# R7FA4L1BD register map
Vendor: Renesas Electronics Corporation; Series: RA4; File version: 0.90.02
CPU: CM33 r0p4, little endian, MPU, FPU, VTOR, 4 interrupt priority bits, 96 interrupts
Registers are 32-bit, read-write, reset 0x0 unless marked. A register's access mark holds for its fields unless they carry their own. Offsets are from the block's base; [hi:lo] are bit positions; {n}, {i} and the like mark numbered series.

## SYSC — System Control
Base 0x4001E000
0x0C SBYCR 16-bit — Standby Control Register
  [15] SSBY — Software Standby Mode Select
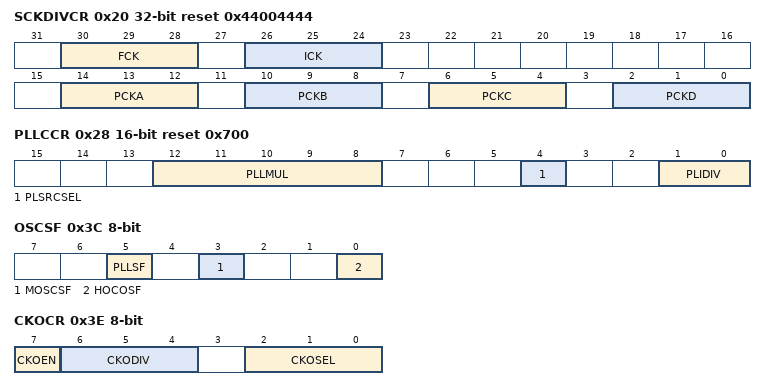
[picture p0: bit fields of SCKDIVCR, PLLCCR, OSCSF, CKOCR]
0x20 SCKDIVCR reset 0x44004444 — System Clock Division Control Register
  [30:28] FCK — FlashIF Clock (FCLK) Select
  [26:24] ICK — System Clock (ICLK) Select
  [14:12] PCKA — Peripheral Module Clock A (PCLKA) Select
  [10:8] PCKB — Peripheral Module Clock B (PCLKB) Select
  [6:4] PCKC — Peripheral Module Clock C (PCLKC) Select
  [2:0] PCKD — Peripheral Module Clock D (PCLKD) Select
0x26 SCKSCR 8-bit reset 0x1 — System Clock Source Control Register
  [2:0] CKSEL — Clock Source Select
0x28 PLLCCR 16-bit reset 0x700 — PLL Clock Control Register
  [12:8] PLLMUL range 0x13..0x3B — PLL Frequency Multiplication Factor Select
  [4] PLSRCSEL — PLL Clock Source Select
  [1:0] PLIDIV — PLL Input Frequency Division Ratio Select
0x2A PLLCR 8-bit reset 0x1 — PLL Control Register
  [0] PLLSTP — PLL Stop Control
0x31 MEMWAIT 8-bit — Memory Wait Cycle Control Register for Code Flash
  [1:0] MEMWAIT — Memory Wait Cycle Select for Code Flash
0x32 MOSCCR 8-bit reset 0x1 — Main Clock Oscillator Control Register
  [0] MOSTP — Main Clock Oscillator Stop
0x36 HOCOCR 8-bit (reset mask 0xFE) — High,Speed On,Chip Oscillator Control Register
  [0] HCSTP — HOCO Stop
0x38 MOCOCR 8-bit — Middle,Speed On,Chip Oscillator Control Register
  [0] MCSTP — MOCO Stop
0x3C OSCSF 8-bit ro (reset mask 0xFE) — Oscillation Stabilization Flag Register
  [5] PLLSF — PLL Clock Oscillation Stabilization Flag
  [3] MOSCSF — Main Clock Oscillation Stabilization Flag
  [0] HOCOSF — HOCO Clock Oscillation Stabilization Flag
0x3E CKOCR 8-bit — Clock Out Control Register
  [7] CKOEN — Clock Out Enable
  [6:4] CKODIV — Clock Output Frequency Division Ratio
  [2:0] CKOSEL — Clock Out Source Select
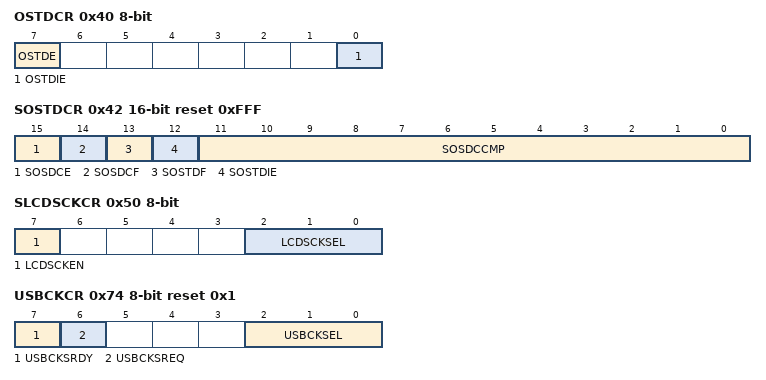
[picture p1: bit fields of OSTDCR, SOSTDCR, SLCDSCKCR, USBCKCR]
0x40 OSTDCR 8-bit — Oscillation Stop Detection Control Register
  [7] OSTDE — Oscillation Stop Detection Function Enable
  [0] OSTDIE — Oscillation Stop Detection Interrupt Enable
0x41 OSTDSR 8-bit — Oscillation Stop Detection Status Register
  [0] OSTDF — Oscillation Stop Detection Flag
0x42 SOSTDCR 16-bit reset 0xFFF — Sub,Clock Oscillation Stop Detection Control Register
  [15] SOSDCE — Control of Sub,Clock Oscillation Stop Detector Operation
  [14] SOSDCF ro — Status of Sub,Clock Oscillation Stop Detector Operation
  [13] SOSTDF ro — Sub,Clock Oscillation Stop Detection Flag
  [12] SOSTDIE — Sub,Clock Oscillation Stop Detection Interrupt Enable
  [11:0] SOSDCCMP — Sub,Clock Oscillation Stop Detection Time
0x50 SLCDSCKCR 8-bit — Segment LCD Source Clock Control Register
  [7] LCDSCKEN — Segment LCD Source Clock (LCDSRCCLK) Out Enable
  [2:0] LCDSCKSEL — Segment LCD Source Clock (LCDSRCCLK) Select
0x61 MOCOUTCR 8-bit — MOCO User Trimming Control Register
  [7:0] MOCOUTRM — MOCO User Trimming
0x62 HOCOUTCR 8-bit — HOCO User Trimming Control Register
  [7:0] HOCOUTRM — HOCO User Trimming
0x6E CANFDCKDIVCR 8-bit — CANFD Clock Division Control Register
  [2:0] CANFDCKDIV — CANFD clock (CANFDCLK) Division Select
0x71 I3CCKDIVCR 8-bit — I3C Clock Division Control Register
  [2:0] I3CCKDIV — I3C Clock (I3CCLK) Division Select
0x74 USBCKCR 8-bit reset 0x1 — USB Clock Control Register
  [7] USBCKSRDY ro — USB Clock (USBCLK) Switching Ready state flag
  [6] USBCKSREQ — USB Clock (USBCLK) Switching Request
  [2:0] USBCKSEL — USB Clock (USBCLK) Source Select
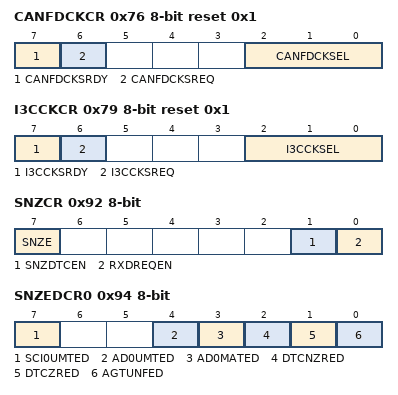
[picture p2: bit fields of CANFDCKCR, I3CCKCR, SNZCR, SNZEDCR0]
0x76 CANFDCKCR 8-bit reset 0x1 — CANFD Clock Control Register
  [7] CANFDCKSRDY ro — CANFD clock (CANFDCLK) Switching Ready State Flag
  [6] CANFDCKSREQ — CANFD clock (CANFDCLK) Switching Request
  [2:0] CANFDCKSEL — CANFD clock (CANFDCLK) Source Select
0x79 I3CCKCR 8-bit reset 0x1 — I3C Clock Control Register
  [7] I3CCKSRDY ro — I3C clock (I3CCLK) Switching Ready State Flag
  [6] I3CCKSREQ — I3C clock (I3CCLK) Switching Request
  [2:0] I3CCKSEL — I3C clock (I3CCLK) Source Select
0x92 SNZCR 8-bit — Snooze Control Register
  [7] SNZE — Snooze mode Enable
  [1] SNZDTCEN — DTC Enable in Snooze mode
  [0] RXDREQEN — RXD0 Snooze Request Enable
0x94 SNZEDCR0 8-bit — Snooze End Control Register 0
  [7] SCI0UMTED — SCI0 Address Mismatch Snooze End Enable
  [4] AD0UMTED — ADC12 Compare Mismatch Snooze End Enable
  [3] AD0MATED — ADC12 Compare Match Snooze End Enable
  [2] DTCNZRED — Not Last DTC Transmission Completion Snooze End Enable
  [1] DTCZRED — Last DTC Transmission Completion Snooze End Enable
  [0] AGTUNFED — AGT1 Underflow Snooze End Enable
0x95 SNZEDCR1 8-bit — Snooze End Control Register 1
  [1] CTSUNAJED — CTSU non,touch automatic judgment Snooze End Enable
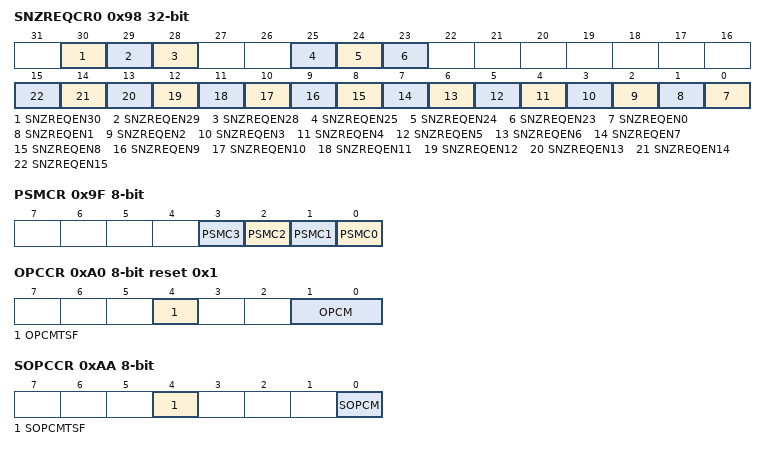
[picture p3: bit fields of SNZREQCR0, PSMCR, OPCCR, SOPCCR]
0x98 SNZREQCR0 — Snooze Request Control Register 0
  [30] SNZREQEN30 — Enable AGT1 compare match B snooze request
  [29] SNZREQEN29 — Enable AGT1 compare match A snooze request
  [28] SNZREQEN28 — Enable AGT1 underflow snooze request
  [25] SNZREQEN25 — Enable RTC period snooze request
  [24] SNZREQEN24 — Enable RTC alarm snooze request
  [23] SNZREQEN23 — Enable ACMP_LP0 snooze request
  [n] SNZREQEN{n} (n=0..15) — Enable IRQ{n} pin snooze request
0x9F PSMCR 8-bit — Power Save Memory Control Register
  [n] PSMC{n} (n=0..3) — Power Save Memory Control bit {n}
0xA0 OPCCR 8-bit reset 0x1 — Operating Power Control Register
  [4] OPCMTSF ro — Operating Power Control Mode Transition Status Flag
  [1:0] OPCM — Operating Power Control Mode Select
0xA2 MOSCWTCR 8-bit reset 0x5 — Main Clock Oscillator Wait Control Register
  [3:0] MSTS — Main Clock Oscillator Wait Time Setting
0xAA SOPCCR 8-bit — Sub Operating Power Control Register
  [4] SOPCMTSF ro — Operating Power Control Mode Transition Status Flag
  [0] SOPCM — Sub Operating Power Control Mode Select
0xAC LDOCR 8-bit — LDO Control Register
  [0] CHG0 — Charge up 0
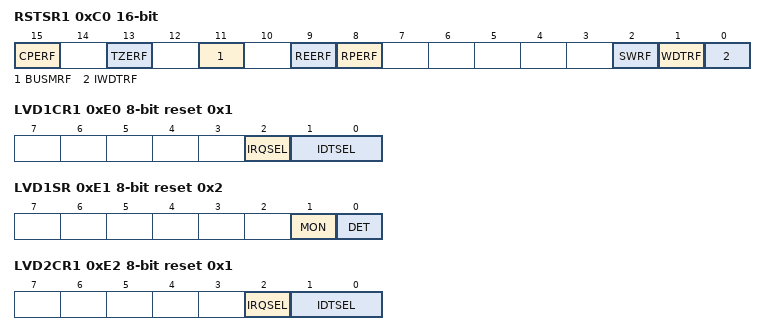
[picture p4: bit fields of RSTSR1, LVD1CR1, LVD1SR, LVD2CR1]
0xC0 RSTSR1 16-bit (reset mask 0x54F8) — Reset Status Register 1
  [15] CPERF — Cache Parity Error Reset Detect Flag
  [13] TZERF — TrustZone Error Reset Detect Flag
  [11] BUSMRF — Bus Master MPU Error Reset Detect Flag
  [9] REERF — SRAM ECC Error Reset Detect Flag
  [8] RPERF — SRAM Parity Error Reset Detect Flag
  [2] SWRF — Software Reset Detect Flag
  [1] WDTRF — Watchdog Timer Reset Detect Flag
  [0] IWDTRF — Independent Watchdog Timer Reset Detect Flag
0xE0 LVD1CR1 8-bit reset 0x1 — Voltage Monitor 1 Circuit Control Register
  [2] IRQSEL — Voltage Monitor 1 Interrupt Type Select
  [1:0] IDTSEL — Voltage Monitor 1 Interrupt Generation Condition Select
0xE1 LVD1SR 8-bit reset 0x2 — Voltage Monitor 1 Circuit Status Register
  [1] MON ro — Voltage Monitor 1 Signal Monitor Flag
  [0] DET — Voltage Monitor 1 Voltage Variation Detection Flag
0xE2 LVD2CR1 8-bit reset 0x1 — Voltage Monitor 2 Circuit Control Register 1
  [2] IRQSEL — Voltage Monitor 2 Interrupt Type Select
  [1:0] IDTSEL — Voltage Monitor 2 Interrupt Generation Condition Select
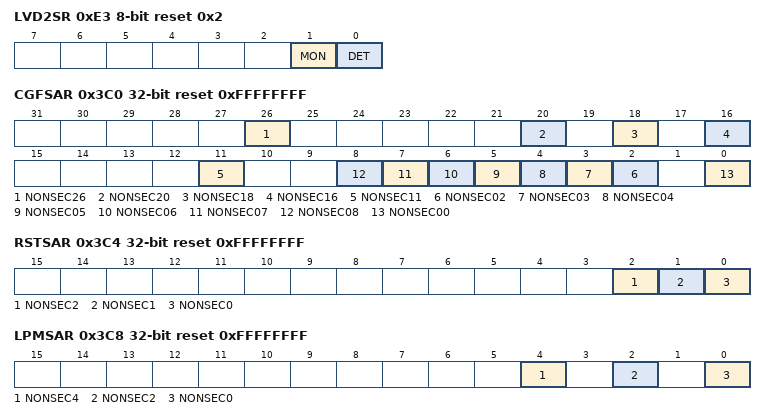
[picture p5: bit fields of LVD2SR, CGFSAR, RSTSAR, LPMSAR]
0xE3 LVD2SR 8-bit reset 0x2 — Voltage Monitor 2 Circuit Status Register
  [1] MON ro — Voltage Monitor 2 Signal Monitor Flag
  [0] DET — Voltage Monitor 2 Voltage Variation Detection Flag
0x3C0 CGFSAR reset 0xFFFFFFFF — Clock Generation Function Security Attribute Register
  [26] NONSEC26 — Non Secure Attribute bit 26
  [20] NONSEC20 — Non Secure Attribute bit 20
  [18] NONSEC18 — Non Secure Attribute bit 18
  [16] NONSEC16 — Non Secure Attribute bit 16
  [11] NONSEC11 — Non Secure Attribute bit 11
  [n] NONSEC{n:02} (n=2..8) — Non Secure Attribute bit {n:02}
  [0] NONSEC00 — Non Secure Attribute bit 00
0x3C4 RSTSAR reset 0xFFFFFFFF — Reset Security Attribution Register
  [2] NONSEC2 — Non Secure Attribute bit 2
  [1] NONSEC1 — Non Secure Attribute bit 1
  [0] NONSEC0 — Non Secure Attribute bit 0
0x3C8 LPMSAR reset 0xFFFFFFFF — Low Power Mode Security Attribution Register
  [4] NONSEC4 — Non Secure Attribute bit 4
  [2] NONSEC2 — Non Secure Attribute bit 2
  [0] NONSEC0 — Non Secure Attribute bit 0
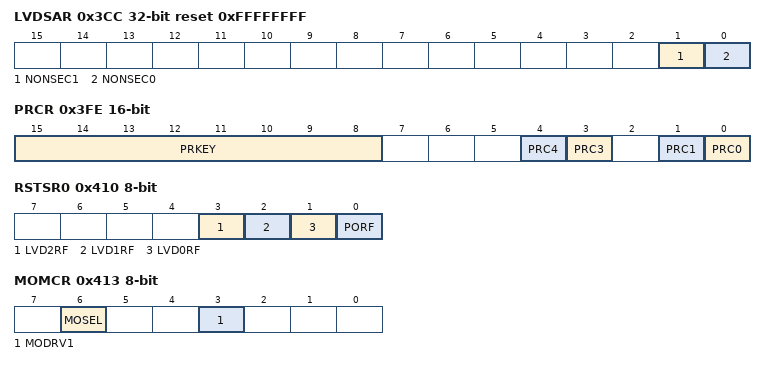
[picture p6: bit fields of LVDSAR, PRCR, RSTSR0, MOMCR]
0x3CC LVDSAR reset 0xFFFFFFFF — Low Voltage Detection Security Attribution Register
  [1] NONSEC1 — Non Secure Attribute bit 1
  [0] NONSEC0 — Non Secure Attribute bit 0
0x3FE PRCR 16-bit — Protect Register
  [15:8] PRKEY wo — PRC Key Code
  [4] PRC4
  [3] PRC3 — Enable writing to the registers related to the LVD
  [1] PRC1 — Enable writing to the registers related to the low power modes
  [0] PRC0 — Enable writing to the registers related to the clock generation circuit
0x40E SYOCDCR 8-bit — System Control OCD Control Register
  [7] DBGEN — Debugger Enable bit
0x410 RSTSR0 8-bit (reset mask 0xF0) — Reset Status Register 0
  [3] LVD2RF — Voltage Monitor 2 Reset Detect Flag
  [2] LVD1RF — Voltage Monitor 1 Reset Detect Flag
  [1] LVD0RF — Voltage Monitor 0 Reset Detect Flag
  [0] PORF — Power,On Reset Detect Flag
0x411 RSTSR2 8-bit (reset mask 0xFE) — Reset Status Register 2
  [0] CWSF — Cold/Warm Start Determination Flag
0x413 MOMCR 8-bit — Main Clock Oscillator Mode Oscillation Control Register
  [6] MOSEL — Main Clock Oscillator Switching
  [3] MODRV1 — Main Clock Oscillator Drive Capability 1 Switching
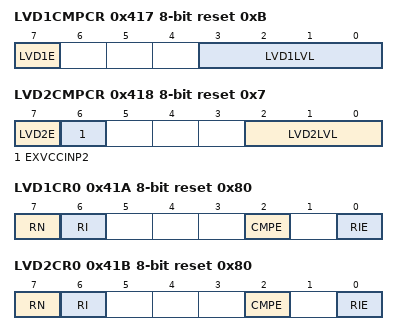
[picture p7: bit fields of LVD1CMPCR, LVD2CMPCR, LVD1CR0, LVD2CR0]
0x417 LVD1CMPCR 8-bit reset 0xB — Voltage Monitoring 1 Comparator Control Register
  [7] LVD1E — Voltage Detection 1 Enable
  [3:0] LVD1LVL — Voltage Detection 1 Level Select
0x418 LVD2CMPCR 8-bit reset 0x7 — Voltage Monitoring 2 Comparator Control Register
  [7] LVD2E — Voltage Detection 2 Enable
  [6] EXVCCINP2 — Voltage Detection 2 Comparison (Voltage external input select)
  [2:0] LVD2LVL — Voltage Detection 2 Level Select
0x41A LVD1CR0 8-bit reset 0x80 — Voltage Monitor 1 Circuit Control Register 0
  [7] RN — Voltage Monitor 1 Reset Negate Select
  [6] RI — Voltage Monitor 1 Circuit Mode Select
  [2] CMPE — Voltage Monitor 1 Circuit Comparison Result Output Enable
  [0] RIE — Voltage Monitor 1 Interrupt/Reset Enable
0x41B LVD2CR0 8-bit reset 0x80 — Voltage Monitor 2 Circuit Control Register 0
  [7] RN — Voltage Monitor 2 Reset Negate Select
  [6] RI — Voltage Monitor 2 Circuit Mode Select
  [2] CMPE — Voltage Monitor 2 Circuit Comparison Result Output Enable
  [0] RIE — Voltage Monitor 2 Interrupt/Reset Enable
0x480 SOSCCR 8-bit reset 0x1 — Sub,Clock Oscillator Control Register
  [0] SOSTP — Sub Clock Oscillator Stop
0x481 SOMCR 8-bit — Sub,Clock Oscillator Mode Control Register
  [1:0] SODRV — Sub,Clock Oscillator Drive Capability Switching
0x482 SOMRG 8-bit — Sub,Clock Oscillator Margin Check Register
  [1:0] SOSCMRG — Sub Clock Oscillator Margin check Switching
0x490 LOCOCR 8-bit — Low,Speed On,Chip Oscillator Control Register
  [0] LCSTP — LOCO Stop
0x492 LOCOUTCR 8-bit — LOCO User Trimming Control Register
  [7:0] LOCOUTRM — LOCO User Trimming
